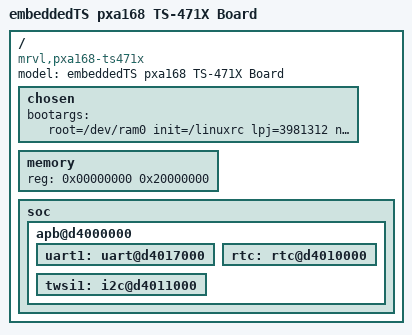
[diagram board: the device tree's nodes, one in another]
/*
 *  Copyright (C) 2012 Marvell Technology Group Ltd.
 *  Author: Haojian Zhuang <haojian.zhuang@marvell.com>
 *
 *  This program is free software; you can redistribute it and/or modify
 *  it under the terms of the GNU General Public License version 2 as
 *  publishhed by the Free Software Foundation.
 */

/dts-v1/; 
/include/ "pxa168.dtsi"

/ {
	model = "embeddedTS pxa168 TS-471X Board";
	compatible = "mrvl,pxa168-ts471x", "mrvl,pxa168";

	chosen {
		bootargs = " root=/dev/ram0 init=/linuxrc lpj=3981312 nbd.max_part=63 console=ttyS0,115200";
	};

	memory {
		reg = <0x00000000 0x20000000>;
	};

	soc {
		apb@d4000000 {
			uart1: uart@d4017000 {
				status = "okay";
			};
			twsi1: i2c@d4011000 {
				status = "okay";
			};
			rtc: rtc@d4010000 {
				status = "okay";
			};
		};
	};
};
